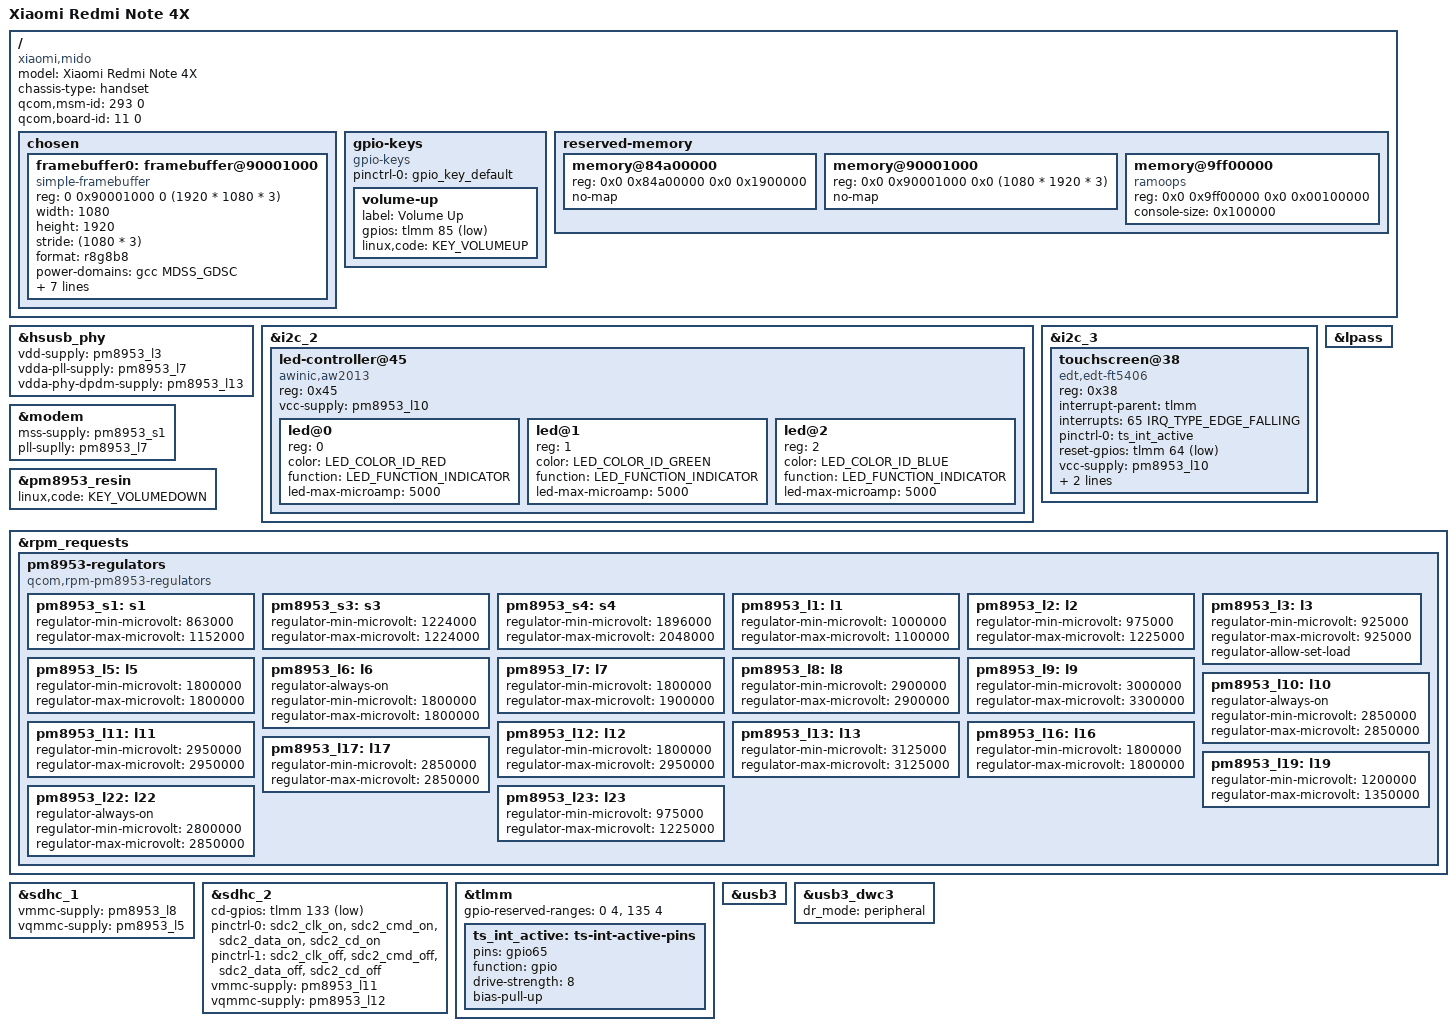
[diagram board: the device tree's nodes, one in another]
/* Copyright (c) 2022 The Linux Foundation. All rights reserved.
 *
 * This program is free software; you can redistribute it and/or modify
 * it under the terms of the GNU General Public License version 2 and
 * only version 2 as published by the Free Software Foundation.
 *
 * This program is distributed in the hope that it will be useful,
 * but WITHOUT ANY WARRANTY; without even the implied warranty of
 * MERCHANTABILITY or FITNESS FOR A PARTICULAR PURPOSE.  See the
 * GNU General Public License for more details.
 */
/dts-v1/;

#include "msm8953.dtsi"
#include "pm8953.dtsi"
#include <dt-bindings/leds/common.h>

/ {
	model = "Xiaomi Redmi Note 4X";
	compatible = "xiaomi,mido", "qcom,msm8953";
	chassis-type = "handset";
	qcom,msm-id = <293 0>;
	qcom,board-id = <11 0>;

	chosen {
		#address-cells = <2>;
		#size-cells = <2>;
		ranges;

		framebuffer0: framebuffer@90001000 {
			compatible = "simple-framebuffer";
			reg = <0 0x90001000 0 (1920 * 1080 * 3)>;

			width = <1080>;
			height = <1920>;
			stride = <(1080 * 3)>;
			format = "r8g8b8";

			power-domains = <&gcc MDSS_GDSC>;

			clocks = <&gcc GCC_MDSS_AHB_CLK>,
				 <&gcc GCC_MDSS_AXI_CLK>,
				 <&gcc GCC_MDSS_VSYNC_CLK>,
				 <&gcc GCC_MDSS_MDP_CLK>,
				 <&gcc GCC_MDSS_BYTE0_CLK>,
				 <&gcc GCC_MDSS_PCLK0_CLK>,
				 <&gcc GCC_MDSS_ESC0_CLK>;
		};
	};

	gpio-keys {
		compatible = "gpio-keys";

		pinctrl-names = "default";
		pinctrl-0 = <&gpio_key_default>;

		volume-up {
			label = "Volume Up";
			gpios = <&tlmm 85 GPIO_ACTIVE_LOW>;
			linux,code = <KEY_VOLUMEUP>;
		};
	};

	reserved-memory {
		/delete-node/memory@85b00000;

		memory@84a00000 {
			reg = <0x0 0x84a00000 0x0 0x1900000>;
			no-map;
		};

		memory@90001000 {
			reg = <0x0 0x90001000 0x0 (1080 * 1920 * 3)>;
			no-map;
		};

		memory@9ff00000 {
			compatible = "ramoops";
			reg = <0x0 0x9ff00000 0x0 0x00100000>;
			console-size = <0x100000>;
		};
	};
};

&hsusb_phy {
	status = "okay";

	vdd-supply = <&pm8953_l3>;
	vdda-pll-supply = <&pm8953_l7>;
	vdda-phy-dpdm-supply = <&pm8953_l13>;
};

&i2c_2 {
	status = "okay";

	led-controller@45 {
		compatible = "awinic,aw2013";
		reg = <0x45>;

		vcc-supply = <&pm8953_l10>;

		#address-cells = <1>;
		#size-cells = <0>;

		led@0 {
			reg = <0>;
			color = <LED_COLOR_ID_RED>;
			function = LED_FUNCTION_INDICATOR;
			led-max-microamp = <5000>;
		};

		led@1 {
			reg = <1>;
			color = <LED_COLOR_ID_GREEN>;
			function = LED_FUNCTION_INDICATOR;
			led-max-microamp = <5000>;
		};

		led@2 {
			reg = <2>;
			color = <LED_COLOR_ID_BLUE>;
			function = LED_FUNCTION_INDICATOR;
			led-max-microamp = <5000>;
		};
	};
};

&i2c_3 {
	status = "okay";

	touchscreen@38 {
		compatible = "edt,edt-ft5406", "edt,edt-ft5x06";
		reg = <0x38>;

		interrupt-parent = <&tlmm>;
		interrupts = <65 IRQ_TYPE_EDGE_FALLING>;

		pinctrl-names = "default";
		pinctrl-0 = <&ts_int_active>;

		reset-gpios = <&tlmm 64 GPIO_ACTIVE_LOW>;

		vcc-supply = <&pm8953_l10>;

		touchscreen-size-x = <1080>;
		touchscreen-size-y = <1920>;
	};
};

&lpass {
	status = "okay";
};

&modem {
	status = "okay";

	mss-supply = <&pm8953_s1>;
	pll-suplly = <&pm8953_l7>;
};

&pm8953_resin {
	status = "okay";
	linux,code = <KEY_VOLUMEDOWN>;
};

&rpm_requests {
	pm8953-regulators {
		compatible = "qcom,rpm-pm8953-regulators";
		// TODO Add supplies

		pm8953_s1: s1 {
			regulator-min-microvolt = <863000>;
			regulator-max-microvolt = <1152000>;
		};

		pm8953_s3: s3 {
			regulator-min-microvolt = <1224000>;
			regulator-max-microvolt = <1224000>;
		};

		pm8953_s4: s4 {
			regulator-min-microvolt = <1896000>;
			regulator-max-microvolt = <2048000>;
		};

		pm8953_l1: l1 {
			regulator-min-microvolt = <1000000>;
			regulator-max-microvolt = <1100000>;
		};

		pm8953_l2: l2 {
			regulator-min-microvolt = <975000>;
			regulator-max-microvolt = <1225000>;
		};

		pm8953_l3: l3 {
			regulator-min-microvolt = <925000>;
			regulator-max-microvolt = <925000>;
			regulator-allow-set-load;
		};

		pm8953_l5: l5 {
			regulator-min-microvolt = <1800000>;
			regulator-max-microvolt = <1800000>;
		};

		pm8953_l6: l6 {
			regulator-always-on;
			regulator-min-microvolt = <1800000>;
			regulator-max-microvolt = <1800000>;
		};

		pm8953_l7: l7 {
			regulator-min-microvolt = <1800000>;
			regulator-max-microvolt = <1900000>;
		};

		pm8953_l8: l8 {
			regulator-min-microvolt = <2900000>;
			regulator-max-microvolt = <2900000>;
		};

		pm8953_l9: l9 {
			regulator-min-microvolt = <3000000>;
			regulator-max-microvolt = <3300000>;
		};

		pm8953_l10: l10 {
			regulator-always-on;
			regulator-min-microvolt = <2850000>;
			regulator-max-microvolt = <2850000>;
		};

		pm8953_l11: l11 {
			regulator-min-microvolt = <2950000>;
			regulator-max-microvolt = <2950000>;
		};

		pm8953_l12: l12 {
			regulator-min-microvolt = <1800000>;
			regulator-max-microvolt = <2950000>;
		};

		pm8953_l13: l13 {
			regulator-min-microvolt = <3125000>;
			regulator-max-microvolt = <3125000>;
		};

		pm8953_l16: l16 {
			regulator-min-microvolt = <1800000>;
			regulator-max-microvolt = <1800000>;
		};

		pm8953_l17: l17 {
			regulator-min-microvolt = <2850000>;
			regulator-max-microvolt = <2850000>;
		};

		pm8953_l19: l19 {
			regulator-min-microvolt = <1200000>;
			regulator-max-microvolt = <1350000>;
		};

		pm8953_l22: l22 {
			regulator-always-on;
			regulator-min-microvolt = <2800000>;
			regulator-max-microvolt = <2850000>;
		};

		pm8953_l23: l23 {
			regulator-min-microvolt = <975000>;
			regulator-max-microvolt = <1225000>;
		};
	};
};

&sdhc_1 {
	status = "okay";

	vmmc-supply = <&pm8953_l8>;
	vqmmc-supply = <&pm8953_l5>;
};

&sdhc_2 {
	status = "okay";

	cd-gpios = <&tlmm 133 GPIO_ACTIVE_LOW>;

	pinctrl-names = "default", "sleep";
	pinctrl-0 = <&sdc2_clk_on &sdc2_cmd_on &sdc2_data_on &sdc2_cd_on>;
	pinctrl-1 = <&sdc2_clk_off &sdc2_cmd_off &sdc2_data_off &sdc2_cd_off>;

	vmmc-supply = <&pm8953_l11>;
	vqmmc-supply = <&pm8953_l12>;
};

&tlmm {
	gpio-reserved-ranges = <0 4>, <135 4>;

	ts_int_active: ts-int-active-pins {
		pins = "gpio65";
		function = "gpio";
		drive-strength = <8>;
		bias-pull-up;
	};
};

&usb3 {
	status = "okay";
};

&usb3_dwc3 {
	dr_mode = "peripheral";
};
